NS_ :

BS_:

BU_:
	NEO
	MCU
	GTW
	EPAS
	DI
	ESP
	SBW
	STW
	APP
	DAS
	XXX

VAL_TABLE_ StW_AnglHP_Spd 16383 "SNA" ;
VAL_TABLE_ DI_aebFaultReason 15 "DI_AEB_FAULT_DAS_REQ_DI_UNAVAIL" 14 "DI_AEB_FAULT_ACCEL_REQ_INVALID" 13 "DI_AEB_FAULT_MIN_TIME_BTWN_EVENTS" 12 "DI_AEB_FAULT_ESP_MIA" 11 "DI_AEB_FAULT_ESP_FAULT" 10 "DI_AEB_FAULT_EPB_NOT_PARKED" 9 "DI_AEB_FAULT_ACCEL_OUT_OF_BOUNDS" 8 "DI_AEB_FAULT_PM_REQUEST" 7 "DI_AEB_FAULT_VEL_EST_ABNORMAL" 6 "DI_AEB_FAULT_DAS_SNA" 5 "DI_AEB_FAULT_DAS_CONTROL_MIA" 4 "DI_AEB_FAULT_SPEED_DELTA" 3 "DI_AEB_FAULT_EBR_FAULT" 2 "DI_AEB_FAULT_PM_MIA" 1 "DI_AEB_FAULT_EPB_MIA" 0 "DI_AEB_FAULT_NONE" ;
VAL_TABLE_ DI_aebLockState 3 "AEB_LOCK_STATE_SNA" 2 "AEB_LOCK_STATE_UNUSED" 1 "AEB_LOCK_STATE_UNLOCKED" 0 "AEB_LOCK_STATE_LOCKED" ;
VAL_TABLE_ DI_aebSmState 7 "DI_AEB_STATE_FAULT" 6 "DI_AEB_STATE_EXIT" 5 "DI_AEB_STATE_STANDSTILL" 4 "DI_AEB_STATE_STOPPING" 3 "DI_AEB_STATE_ENABLE" 2 "DI_AEB_STATE_ENABLE_INIT" 1 "DI_AEB_STATE_STANDBY" 0 "DI_AEB_STATE_UNAVAILABLE" ;
VAL_TABLE_ DI_aebState 7 "AEB_CAN_STATE_SNA" 4 "AEB_CAN_STATE_FAULT" 3 "AEB_CAN_STATE_STANDSTILL" 2 "AEB_CAN_STATE_ENABLED" 1 "AEB_CAN_STATE_STANDBY" 0 "AEB_CAN_STATE_UNAVAILABLE" ;
VAL_TABLE_ DI_epbInterfaceReady 1 "EPB_INTERFACE_READY" 0 "EPB_INTERFACE_NOT_READY" ;
VAL_TABLE_ DI_gear 7 "DI_GEAR_SNA" 4 "DI_GEAR_D" 3 "DI_GEAR_N" 2 "DI_GEAR_R" 1 "DI_GEAR_P" 0 "DI_GEAR_INVALID" ;
VAL_TABLE_ DI_gpoReason 8 "DI_GPO_NUMREASONS" 7 "DI_GPO_CAPACITOR_OVERTEMP" 6 "DI_GPO_NOT_ENOUGH_12V" 5 "DI_GPO_NO_BATTERY_POWER" 4 "DI_GPO_AMBIENT_OVERTEMP" 3 "DI_GPO_FLUID_DELTAT" 2 "DI_GPO_STATOR_OVERTEMP" 1 "DI_GPO_HEATSINK_OVERTEMP" 0 "DI_GPO_OUTLET_OVERTEMP" ;
VAL_TABLE_ DI_immobilizerCondition 1 "DI_IMM_CONDITION_LEARNED" 0 "DI_IMM_CONDITION_VIRGIN_SNA" ;
VAL_TABLE_ DI_immobilizerState 7 "DI_IMM_STATE_FAULT" 6 "DI_IMM_STATE_FAULTRETRY" 5 "DI_IMM_STATE_RESET" 4 "DI_IMM_STATE_LEARN" 3 "DI_IMM_STATE_DISARMED" 2 "DI_IMM_STATE_AUTHENTICATING" 1 "DI_IMM_STATE_REQUEST" 0 "DI_IMM_STATE_INIT_SNA" ;
VAL_TABLE_ DI_limpReason 24 "DI_LIMP_NUMREASONS" 23 "DI_LIMP_CAPACITOR_OVERTEMP" 22 "DI_LIMP_GTW_MIA" 21 "DI_LIMP_TRQCMD_VALIDITY_UNKNOWN" 20 "DI_LIMP_DI_MIA" 19 "DI_LIMP_CONFIG_MISMATCH" 18 "DI_LIMP_HEATSINK_TEMP" 17 "DI_LIMP_PMREQUEST" 16 "DI_LIMP_PMHEARTBEAT" 15 "DI_LIMP_TRQ_CROSS_CHECK" 14 "DI_LIMP_EXTERNAL_COMMAND" 13 "DI_LIMP_WRONG_CS_CALIBRATION" 12 "DI_LIMP_STATOR_TEMP" 11 "DI_LIMP_DELTAT_TOO_NEGATIVE" 10 "DI_LIMP_DELTAT_TOO_POSITIVE" 9 "DI_LIMP_AMBIENT_TEMP" 8 "DI_LIMP_OUTLET_TEMP" 7 "DI_LIMP_LOW_FLOW" 6 "DI_LIMP_BMS_MIA" 5 "DI_LIMP_12V_SUPPLY_UNDERVOLTAGE" 4 "DI_LIMP_NO_FLUID" 3 "DI_LIMP_NO_FUNC_HEATSINK_SENSOR" 2 "DI_LIMP_NO_FUNC_STATORT_SENSOR" 1 "DI_LIMP_BUSV_SENSOR_IRRATIONAL" 0 "DI_LIMP_PHASE_IMBALANCE" ;
VAL_TABLE_ DI_mode 2 "DI_MODE_DYNO" 1 "DI_MODE_DRIVE" 0 "DI_MODE_UNDEF" ;
VAL_TABLE_ DI_motorType 14 "DI_MOTOR_F2AE" 13 "DI_MOTOR_F2AD" 12 "DI_MOTOR_F2AC" 11 "DI_MOTOR_F2AB" 10 "DI_MOTOR_F1AC" 9 "DI_MOTOR_SSR1A" 8 "DI_MOTOR_F1A" 7 "DI_MOTOR_M7M6" 6 "DI_MOTOR_M8A" 5 "DI_MOTOR_M7M5" 4 "DI_MOTOR_M7M4" 3 "DI_MOTOR_M7M3" 2 "DI_MOTOR_ROADSTER_SPORT" 1 "DI_MOTOR_ROADSTER_BASE" 0 "DI_MOTOR_SNA" ;
VAL_TABLE_ DI_speedUnits 1 "DI_SPEED_KPH" 0 "DI_SPEED_MPH" ;
VAL_TABLE_ DI_state 4 "DI_STATE_ENABLE" 3 "DI_STATE_FAULT" 2 "DI_STATE_CLEAR_FAULT" 1 "DI_STATE_STANDBY" 0 "DI_STATE_PREAUTH" ;
VAL_TABLE_ DI_velocityEstimatorState 4 "VE_STATE_BACKUP_MOTOR" 3 "VE_STATE_BACKUP_WHEELS_B" 2 "VE_STATE_BACKUP_WHEELS_A" 1 "VE_STATE_WHEELS_NORMAL" 0 "VE_STATE_NOT_INITIALIZED" ;

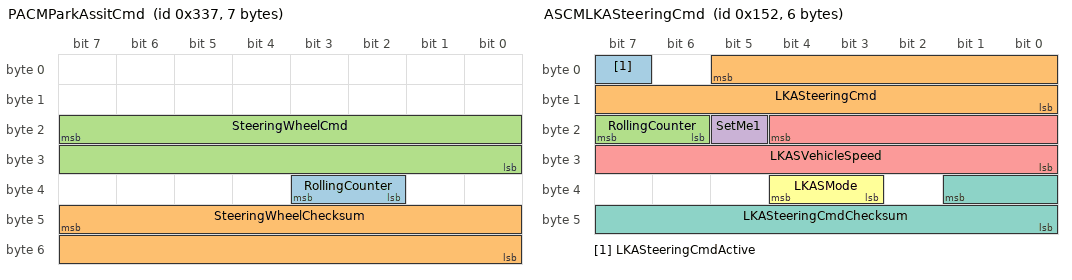
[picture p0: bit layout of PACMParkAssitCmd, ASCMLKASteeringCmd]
BO_ 823 PACMParkAssitCmd: 7 NEO
 SG_ RollingCounter : 35|2@0+ (1,0) [0|0] ""  NEO
 SG_ SteeringWheelChecksum : 47|16@0+ (1,0) [0|0] ""  NEO
 SG_ SteeringWheelCmd : 23|16@0+ (1,0) [0|0] ""  NEO

BO_ 560 EBCMRegen: 6 K17_EBCM
 SG_ Regen : 1|10@0+ (1,0) [0|0] ""  NEO

BO_ 338 ASCMLKASteeringCmd: 6 NEO
 SG_ LKASteeringCmdActive : 7|1@0+ (1,0) [0|0] ""  NEO
 SG_ LKASteeringCmd : 5|14@0- (1,0) [0|0] ""  NEO
 SG_ RollingCounter : 23|2@0+ (1,0) [0|0] ""  NEO
 SG_ SetMe1 : 21|1@0+ (1,0) [0|0] ""  NEO
 SG_ LKASVehicleSpeed : 20|13@0+ (0.22,0) [0|0] "kph" NEO
 SG_ LKASMode : 36|2@0+ (1,0) [0|0] ""  NEO
 SG_ LKASteeringCmdChecksum : 33|10@0+ (1,0) [0|0] ""  NEO

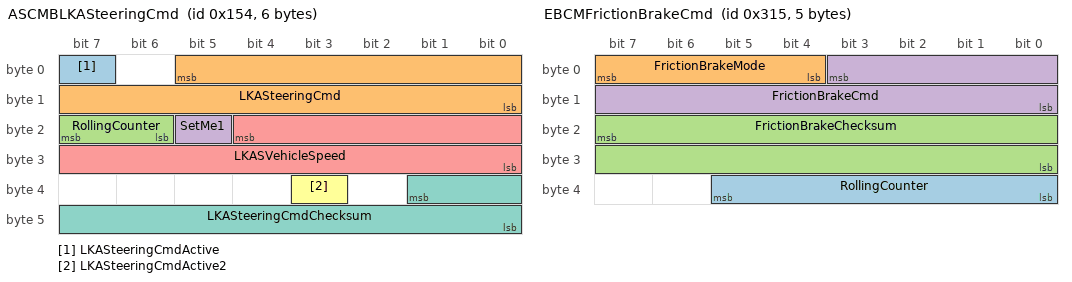
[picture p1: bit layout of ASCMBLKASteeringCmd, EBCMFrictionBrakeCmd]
BO_ 340 ASCMBLKASteeringCmd: 6 NEO
 SG_ LKASteeringCmdActive : 7|1@0+ (1,0) [0|0] ""  NEO
 SG_ LKASteeringCmd : 5|14@0- (1,0) [0|0] ""  NEO
 SG_ RollingCounter : 23|2@0+ (1,0) [0|0] ""  NEO
 SG_ SetMe1 : 21|1@0+ (1,0) [0|0] ""  NEO
 SG_ LKASVehicleSpeed : 20|13@0+ (0.22,0) [0|0] "kph" NEO
 SG_ LKASteeringCmdActive2 : 35|1@0+ (1,0) [0|0] ""  NEO
 SG_ LKASteeringCmdChecksum : 33|10@0+ (1,0) [0|0] ""  NEO

BO_ 368 EBCMFrictionBrakeStatus: 8 K17_EBCM
 SG_ FrictionBrakePressure : 23|16@0+ (1,0) [0|0] ""  NEO

BO_ 789 EBCMFrictionBrakeCmd: 5 K17_EBCM
 SG_ RollingCounter : 37|6@0+ (1,0) [0|0] ""  NEO
 SG_ FrictionBrakeMode : 7|4@0+ (1,0) [0|0] ""  NEO
 SG_ FrictionBrakeChecksum : 23|16@0+ (1,0) [0|0] ""  NEO
 SG_ FrictionBrakeCmd : 3|12@0- (1,0) [0|0] ""  NEO

BO_TX_BU_ 823 : K43_PSCM,NEO;
BO_TX_BU_ 789 : NEO,K17_EBCM;

BU_: XXX

CM_ SG_ 31 GEAR "13-P, 12-R, 11-N, 1-6-D";
VAL_ 552 GEAR 1 "P" 2 "R" 3 "N" 4 "D" ;
VAL_ 540 RADAR_HAS_LEAD 0 "NO LEAD" 1 "HAS LEAD" ;
VAL_ 540 RADAR_LEAD_RELATIVE_DISTANCE 0 "NO LEAD" 1 "FARTHEST" 2 "4" 3 "3" 4 "2" 5 "NEAREST" ;
VAL_ 1143 LEFT_BS_STATUS 0 "No object detected" 1 "Object detected in left blindspot" 2 "Object detected in left blindspot with blinker - warning"
